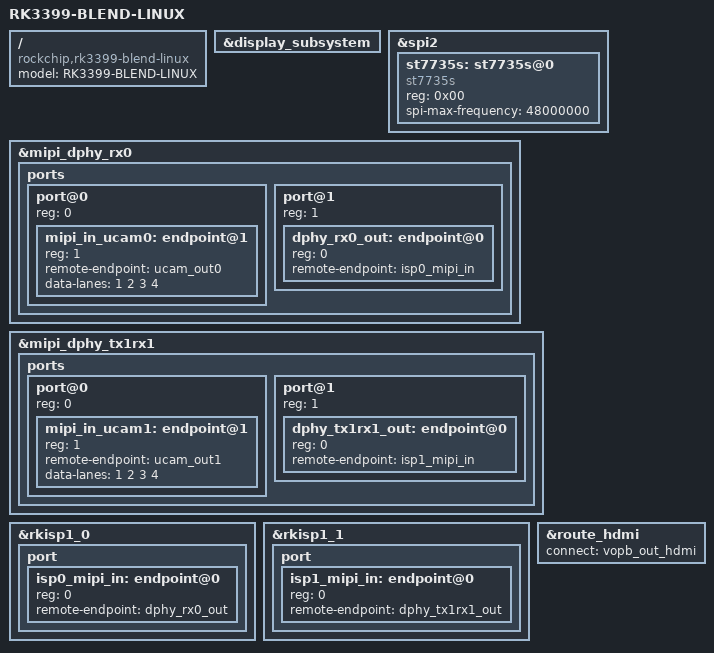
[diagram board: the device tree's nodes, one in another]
// SPDX-License-Identifier: (GPL-2.0+ OR MIT)
/*
 * Copyright (c) 2018 Fuzhou Rockchip Electronics Co., Ltd
 */

/dts-v1/;
#include "rk3399-blend.dtsi"
#include "rk3399-linux.dtsi"

/ {
	model = "RK3399-BLEND-LINUX";
	compatible = "rockchip,rk3399-blend-linux", "rockchip,rk3399";
	
	
};

&display_subsystem {
	status = "okay";
};

&spi2{
	st7735s:st7735s@0 {
			compatible = "st7735s";
			reg = <0x00>;
			spi-max-frequency = < 48000000>;
			status = "okay";
			};
}
&mipi_dphy_rx0 {
	status = "okay";

	ports {
		#address-cells = <1>;
		#size-cells = <0>;

		port@0 {
			reg = <0>;
			#address-cells = <1>;
			#size-cells = <0>;

			mipi_in_ucam0: endpoint@1 {
				reg = <1>;
				remote-endpoint = <&ucam_out0>;
				data-lanes = <1 2 3 4>;
			};
		};

		port@1 {
			reg = <1>;
			#address-cells = <1>;
			#size-cells = <0>;

			dphy_rx0_out: endpoint@0 {
				reg = <0>;
				remote-endpoint = <&isp0_mipi_in>;
			};
		};
	};
};

&mipi_dphy_tx1rx1 {
	status = "okay";

	ports {
		#address-cells = <1>;
		#size-cells = <0>;

		port@0 {
			reg = <0>;
			#address-cells = <1>;
			#size-cells = <0>;

			mipi_in_ucam1: endpoint@1 {
				reg = <1>;
				remote-endpoint = <&ucam_out1>;
				data-lanes = <1 2 3 4>;
			};
		};

		port@1 {
			reg = <1>;
			#address-cells = <1>;
			#size-cells = <0>;

			dphy_tx1rx1_out: endpoint@0 {
				reg = <0>;
				remote-endpoint = <&isp1_mipi_in>;
			};
		};
	};
};

&rkisp1_0 {
	status = "okay";

	port {
		#address-cells = <1>;
		#size-cells = <0>;

		isp0_mipi_in: endpoint@0 {
			reg = <0>;
			remote-endpoint = <&dphy_rx0_out>;
		};
	};
};

&rkisp1_1 {
	status = "okay";

	port {
		#address-cells = <1>;
		#size-cells = <0>;

		isp1_mipi_in: endpoint@0 {
			reg = <0>;
			remote-endpoint = <&dphy_tx1rx1_out>;
		};
	};
};

&route_hdmi {
	status = "okay";
	connect = <&vopb_out_hdmi>;
};
